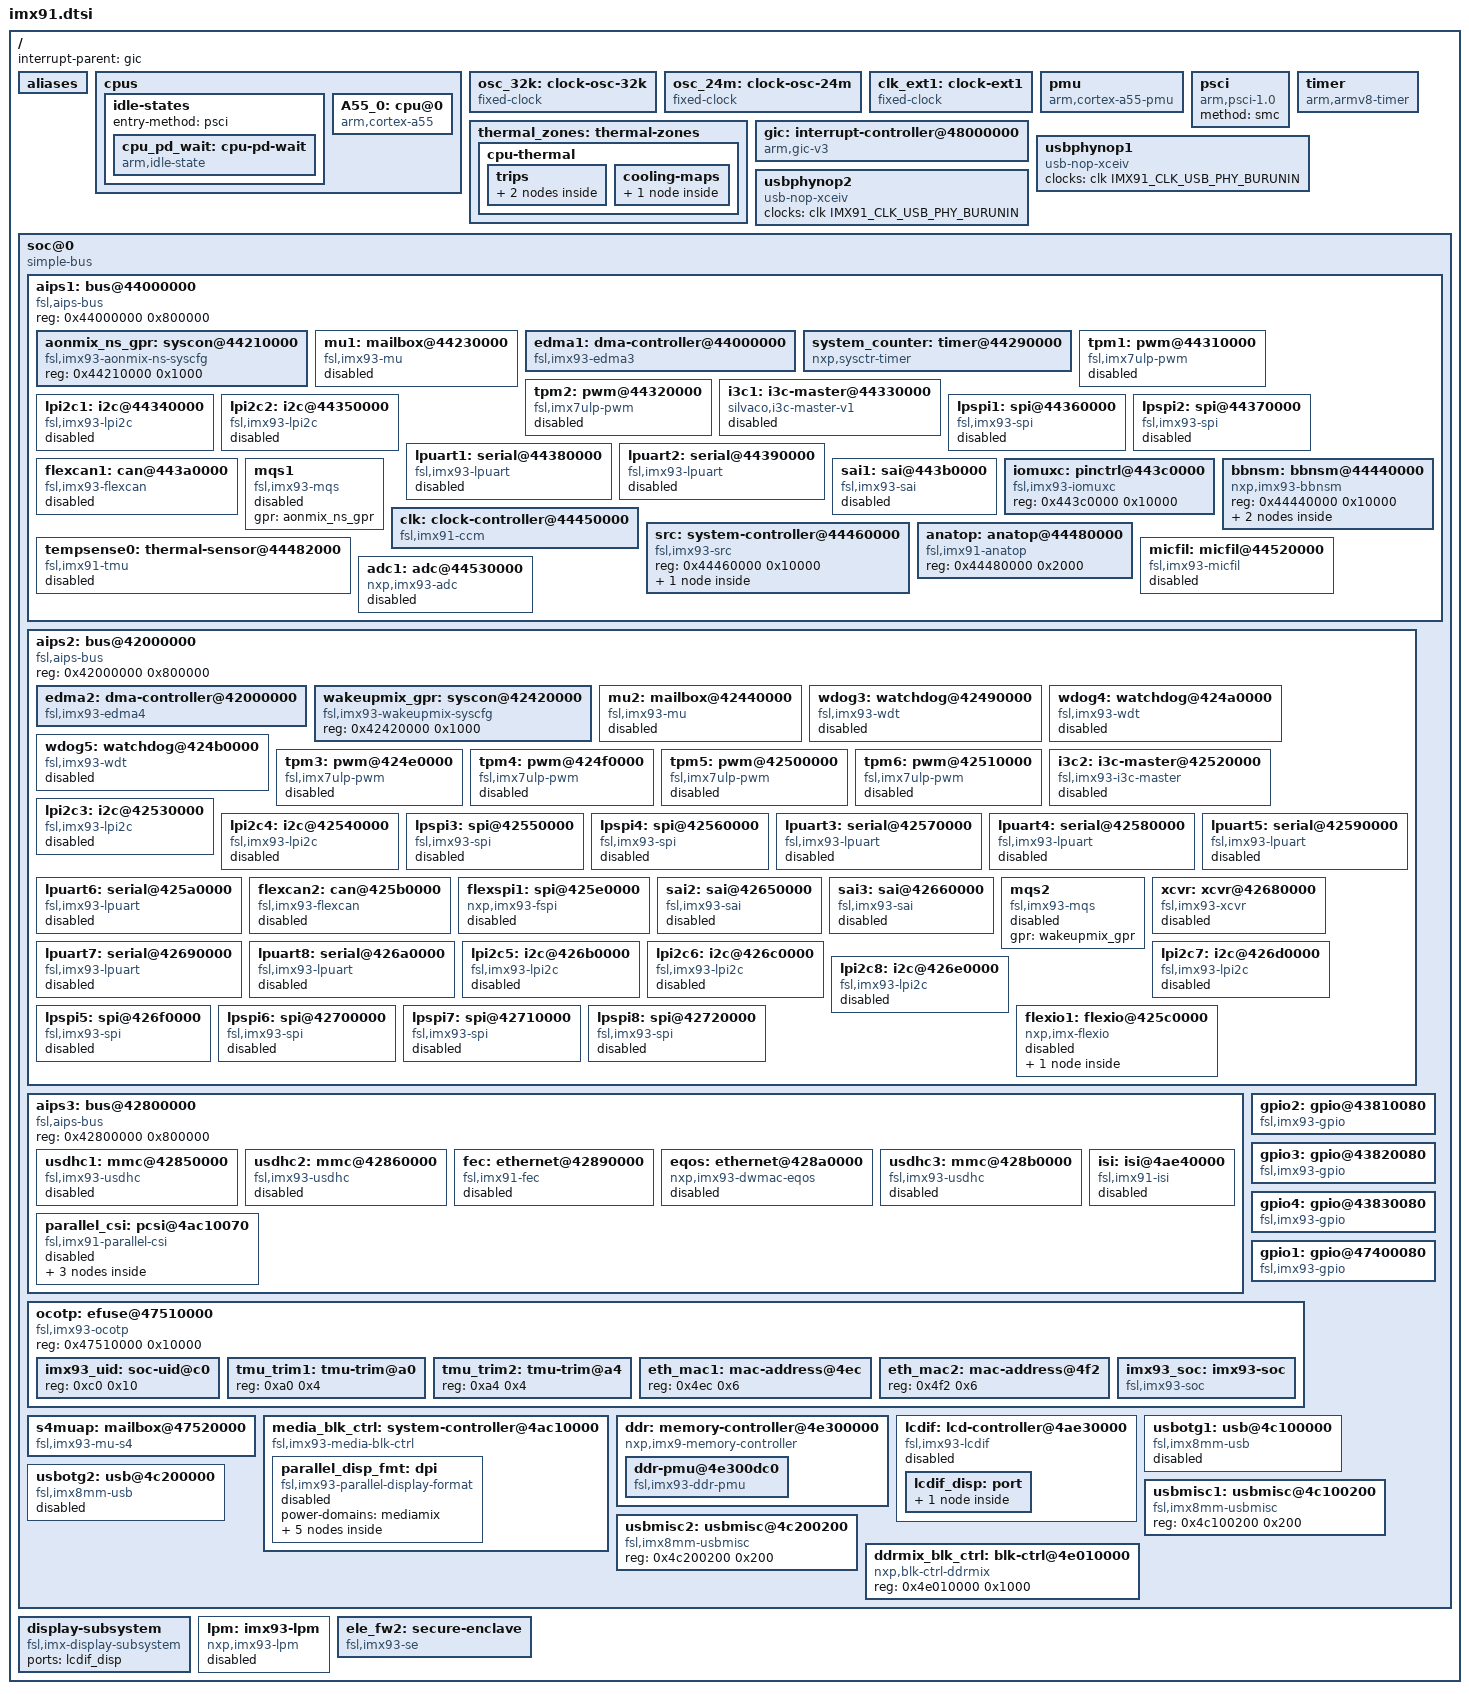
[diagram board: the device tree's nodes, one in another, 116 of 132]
// SPDX-License-Identifier: (GPL-2.0+ OR MIT)
/*
 * Copyright 2024 NXP
 */

#include <dt-bindings/clock/imx91-clock.h>
#include <dt-bindings/gpio/gpio.h>
#include <dt-bindings/input/input.h>
#include <dt-bindings/interrupt-controller/arm-gic.h>
#include <dt-bindings/power/fsl,imx91-power.h>
#include <dt-bindings/thermal/thermal.h>

#include "imx91-pinfunc.h"

/ {
	interrupt-parent = <&gic>;
	#address-cells = <2>;
	#size-cells = <2>;

	aliases {
		gpio0 = &gpio1;
		gpio1 = &gpio2;
		gpio2 = &gpio3;
		gpio3 = &gpio4;
		i2c0 = &lpi2c1;
		i2c1 = &lpi2c2;
		i2c2 = &lpi2c3;
		i2c3 = &lpi2c4;
		i2c4 = &lpi2c5;
		i2c5 = &lpi2c6;
		i2c6 = &lpi2c7;
		i2c7 = &lpi2c8;
		ethernet0 = &fec;
		ethernet1 = &eqos;
		mmc0 = &usdhc1;
		mmc1 = &usdhc2;
		mmc2 = &usdhc3;
		serial0 = &lpuart1;
		serial1 = &lpuart2;
		serial2 = &lpuart3;
		serial3 = &lpuart4;
		serial4 = &lpuart5;
		serial5 = &lpuart6;
		serial6 = &lpuart7;
		serial7 = &lpuart8;
		rtc0 = &bbnsm_rtc;
	};

	cpus {
		#address-cells = <1>;
		#size-cells = <0>;

		idle-states {
			entry-method = "psci";

			cpu_pd_wait: cpu-pd-wait {
				compatible = "arm,idle-state";
				arm,psci-suspend-param = <0x0010033>;
				local-timer-stop;
				entry-latency-us = <10000>;
				exit-latency-us = <7000>;
				min-residency-us = <27000>;
				wakeup-latency-us = <15000>;
			};
		};

		A55_0: cpu@0 {
			device_type = "cpu";
			compatible = "arm,cortex-a55";
			reg = <0x0>;
			enable-method = "psci";
			#cooling-cells = <2>;
			cpu-idle-states = <&cpu_pd_wait>;
		};
	};

	osc_32k: clock-osc-32k {
		compatible = "fixed-clock";
		#clock-cells = <0>;
		clock-frequency = <32768>;
		clock-output-names = "osc_32k";
	};

	osc_24m: clock-osc-24m {
		compatible = "fixed-clock";
		#clock-cells = <0>;
		clock-frequency = <24000000>;
		clock-output-names = "osc_24m";
	};

	clk_ext1: clock-ext1 {
		compatible = "fixed-clock";
		#clock-cells = <0>;
		clock-frequency = <133000000>;
		clock-output-names = "clk_ext1";
	};

	pmu {
		compatible = "arm,cortex-a55-pmu";
		interrupts = <GIC_PPI 7 (GIC_CPU_MASK_SIMPLE(2) | IRQ_TYPE_LEVEL_HIGH)>;
	};

	thermal_zones: thermal-zones {
		cpu-thermal {
			polling-delay-passive = <250>;
			polling-delay = <2000>;
			thermal-sensors = <&tempsense0>;
			trips {
				cpu_alert0: trip0 {
					temperature = <80000>;
					hysteresis = <2000>;
					type = "passive";
				};

				cpu_crit0: trip1 {
					temperature = <90000>;
					hysteresis = <2000>;
					type = "critical";
				};
			};

			cooling-maps {
				map0 {
					trip = <&cpu_alert0>;
					cooling-device =
						<&A55_0 THERMAL_NO_LIMIT THERMAL_NO_LIMIT>,
						<&lpm 0 1>;
				};
			};
		};
	};

	psci {
		compatible = "arm,psci-1.0";
		method = "smc";
	};

	timer {
		compatible = "arm,armv8-timer";
		interrupts = <GIC_PPI 13 (GIC_CPU_MASK_SIMPLE(6) | IRQ_TYPE_LEVEL_LOW)>,
			     <GIC_PPI 14 (GIC_CPU_MASK_SIMPLE(6) | IRQ_TYPE_LEVEL_LOW)>,
			     <GIC_PPI 11 (GIC_CPU_MASK_SIMPLE(6) | IRQ_TYPE_LEVEL_LOW)>,
			     <GIC_PPI 10 (GIC_CPU_MASK_SIMPLE(6) | IRQ_TYPE_LEVEL_LOW)>;
		clock-frequency = <24000000>;
		arm,no-tick-in-suspend;
		interrupt-parent = <&gic>;
	};

	gic: interrupt-controller@48000000 {
		compatible = "arm,gic-v3";
		reg = <0 0x48000000 0 0x10000>,
		      <0 0x48040000 0 0xc0000>;
		#interrupt-cells = <3>;
		interrupt-controller;
		interrupts = <GIC_PPI 9 IRQ_TYPE_LEVEL_HIGH>;
		interrupt-parent = <&gic>;
	};

	usbphynop1: usbphynop1 {
		compatible = "usb-nop-xceiv";
		clocks = <&clk IMX91_CLK_USB_PHY_BURUNIN>;
		clock-names = "main_clk";
	};

	usbphynop2: usbphynop2 {
		compatible = "usb-nop-xceiv";
		clocks = <&clk IMX91_CLK_USB_PHY_BURUNIN>;
		clock-names = "main_clk";
	};

	soc@0 {
		compatible = "simple-bus";
		#address-cells = <1>;
		#size-cells = <1>;
		ranges = <0x0 0x0 0x0 0x80000000>,
			 <0x28000000 0x0 0x28000000 0x10000000>;

		aips1: bus@44000000 {
			compatible = "fsl,aips-bus", "simple-bus";
			reg = <0x44000000 0x800000>;
			#address-cells = <1>;
			#size-cells = <1>;
			ranges;

			aonmix_ns_gpr: syscon@44210000 {
				compatible = "fsl,imx93-aonmix-ns-syscfg", "syscon";
				reg = <0x44210000 0x1000>;
			};

			mu1: mailbox@44230000 {
				compatible = "fsl,imx93-mu", "fsl,imx8ulp-mu";
				reg = <0x44230000 0x10000>;
				interrupts = <GIC_SPI 22 IRQ_TYPE_LEVEL_HIGH>;
				clocks = <&clk IMX91_CLK_MU1_B_GATE>;
				#mbox-cells = <2>;
				status = "disabled";
			};

			edma1: dma-controller@44000000{
				compatible = "fsl,imx93-edma3";
				reg = <0x44000000 0x200000>;
				#dma-cells = <3>;
				dma-channels = <31>;
				interrupts = <GIC_SPI 95 IRQ_TYPE_LEVEL_HIGH>,
					     <GIC_SPI 96 IRQ_TYPE_LEVEL_HIGH>,
					     <GIC_SPI 97 IRQ_TYPE_LEVEL_HIGH>,
					     <GIC_SPI 98 IRQ_TYPE_LEVEL_HIGH>,
					     <GIC_SPI 99 IRQ_TYPE_LEVEL_HIGH>,
					     <GIC_SPI 100 IRQ_TYPE_LEVEL_HIGH>,
					     <GIC_SPI 101 IRQ_TYPE_LEVEL_HIGH>,
					     <GIC_SPI 102 IRQ_TYPE_LEVEL_HIGH>,
					     <GIC_SPI 103 IRQ_TYPE_LEVEL_HIGH>,
					     <GIC_SPI 104 IRQ_TYPE_LEVEL_HIGH>,
					     <GIC_SPI 105 IRQ_TYPE_LEVEL_HIGH>,
					     <GIC_SPI 106 IRQ_TYPE_LEVEL_HIGH>,
					     <GIC_SPI 107 IRQ_TYPE_LEVEL_HIGH>,
					     <GIC_SPI 108 IRQ_TYPE_LEVEL_HIGH>,
					     <GIC_SPI 109 IRQ_TYPE_LEVEL_HIGH>,
					     <GIC_SPI 110 IRQ_TYPE_LEVEL_HIGH>,
					     <GIC_SPI 111 IRQ_TYPE_LEVEL_HIGH>,
					     <GIC_SPI 112 IRQ_TYPE_LEVEL_HIGH>,
					     <GIC_SPI 113 IRQ_TYPE_LEVEL_HIGH>,
					     <GIC_SPI 114 IRQ_TYPE_LEVEL_HIGH>,
					     <GIC_SPI 115 IRQ_TYPE_LEVEL_HIGH>,
					     <GIC_SPI 116 IRQ_TYPE_LEVEL_HIGH>,
					     <GIC_SPI 117 IRQ_TYPE_LEVEL_HIGH>,
					     <GIC_SPI 118 IRQ_TYPE_LEVEL_HIGH>,
					     <GIC_SPI 119 IRQ_TYPE_LEVEL_HIGH>,
					     <GIC_SPI 120 IRQ_TYPE_LEVEL_HIGH>,
					     <GIC_SPI 121 IRQ_TYPE_LEVEL_HIGH>,
					     <GIC_SPI 122 IRQ_TYPE_LEVEL_HIGH>,
					     <GIC_SPI 123 IRQ_TYPE_LEVEL_HIGH>,
					     <GIC_SPI 124 IRQ_TYPE_LEVEL_HIGH>,
					     <GIC_SPI 125 IRQ_TYPE_LEVEL_HIGH>,
					     <GIC_SPI 94 IRQ_TYPE_LEVEL_HIGH>;
				clocks = <&clk IMX91_CLK_EDMA1_GATE>;
				clock-names = "dma";
				status = "okay";
			};

			system_counter: timer@44290000 {
				compatible = "nxp,sysctr-timer";
				reg = <0x44290000 0x30000>;
				interrupts = <GIC_SPI 74 IRQ_TYPE_LEVEL_HIGH>;
				clocks = <&osc_24m>;
				clock-names = "per";
				nxp,no-divider;
			};

			tpm1: pwm@44310000 {
				compatible = "fsl,imx7ulp-pwm";
				reg = <0x44310000 0x1000>;
				clocks = <&clk IMX91_CLK_TPM1_GATE>;
				#pwm-cells = <3>;
				status = "disabled";
			};

			tpm2: pwm@44320000 {
				compatible = "fsl,imx7ulp-pwm";
				reg = <0x44320000 0x1000>;
				clocks = <&clk IMX91_CLK_TPM2_GATE>;
				assigned-clocks = <&clk IMX91_CLK_TPM2>;
				assigned-clock-parents = <&clk IMX91_CLK_24M>;
				assigned-clock-rates = <24000000>;
				#pwm-cells = <3>;
				status = "disabled";
			};

			i3c1: i3c-master@44330000 {
				#address-cells = <3>;
				#size-cells = <0>;
				compatible = "silvaco,i3c-master-v1";
				reg = <0x44330000 0x10000>;
				interrupts = <GIC_SPI 12 IRQ_TYPE_LEVEL_HIGH>;
				clocks = <&clk IMX91_CLK_BUS_AON>,
					 <&clk IMX91_CLK_I3C1_GATE>,
					 <&clk IMX91_CLK_DUMMY>;
				clock-names = "pclk", "fast_clk", "slow_clk";
				status = "disabled";
			};

			lpi2c1: i2c@44340000 {
				compatible = "fsl,imx93-lpi2c", "fsl,imx7ulp-lpi2c";
				reg = <0x44340000 0x10000>;
				#address-cells = <1>;
				#size-cells = <0>;
				interrupts = <GIC_SPI 13 IRQ_TYPE_LEVEL_HIGH>;
				clocks = <&clk IMX91_CLK_LPI2C1_GATE>,
					 <&clk IMX91_CLK_BUS_AON>;
				clock-names = "per", "ipg";
				dmas = <&edma1 7 0 0>, <&edma1 8 0 1>;
				dma-names = "tx","rx";
				status = "disabled";
			};

			lpi2c2: i2c@44350000 {
				compatible = "fsl,imx93-lpi2c", "fsl,imx7ulp-lpi2c";
				reg = <0x44350000 0x10000>;
				#address-cells = <1>;
				#size-cells = <0>;
				interrupts = <GIC_SPI 14 IRQ_TYPE_LEVEL_HIGH>;
				clocks = <&clk IMX91_CLK_LPI2C2_GATE>,
					 <&clk IMX91_CLK_BUS_AON>;
				clock-names = "per", "ipg";
				dmas = <&edma1 9 0 0>, <&edma1 10 0 1>;
				dma-names = "tx","rx";
				status = "disabled";
			};

			lpspi1: spi@44360000 {
				#address-cells = <1>;
				#size-cells = <0>;
				compatible = "fsl,imx93-spi", "fsl,imx7ulp-spi";
				reg = <0x44360000 0x10000>;
				interrupts = <GIC_SPI 16 IRQ_TYPE_LEVEL_HIGH>;
				clocks = <&clk IMX91_CLK_LPSPI1_GATE>,
					 <&clk IMX91_CLK_BUS_AON>;
				clock-names = "per", "ipg";
				dmas = <&edma1 11 0 0>, <&edma1 12 0 1>;
				dma-names = "tx","rx";
				status = "disabled";
			};

			lpspi2: spi@44370000 {
				#address-cells = <1>;
				#size-cells = <0>;
				compatible = "fsl,imx93-spi", "fsl,imx7ulp-spi";
				reg = <0x44370000 0x10000>;
				interrupts = <GIC_SPI 17 IRQ_TYPE_LEVEL_HIGH>;
				clocks = <&clk IMX91_CLK_LPSPI2_GATE>,
					 <&clk IMX91_CLK_BUS_AON>;
				clock-names = "per", "ipg";
				dmas = <&edma1 13 0 0>, <&edma1 14 0 1>;
				dma-names = "tx","rx";
				status = "disabled";
			};

			lpuart1: serial@44380000 {
				compatible = "fsl,imx93-lpuart", "fsl,imx8ulp-lpuart", "fsl,imx7ulp-lpuart";
				reg = <0x44380000 0x1000>;
				interrupts = <GIC_SPI 19 IRQ_TYPE_LEVEL_HIGH>;
				clocks = <&clk IMX91_CLK_LPUART1_GATE>;
				clock-names = "ipg";
				dmas = <&edma1 17 0 1>, <&edma1 16 0 0>;
				dma-names = "rx", "tx";
				status = "disabled";
			};

			lpuart2: serial@44390000 {
				compatible = "fsl,imx93-lpuart", "fsl,imx8ulp-lpuart", "fsl,imx7ulp-lpuart";
				reg = <0x44390000 0x1000>;
				interrupts = <GIC_SPI 20 IRQ_TYPE_LEVEL_HIGH>;
				clocks = <&clk IMX91_CLK_LPUART2_GATE>;
				clock-names = "ipg";
				dmas = <&edma1 19 0 1>, <&edma1 18 0 0>;
				dma-names = "rx", "tx";
				status = "disabled";
			};

			flexcan1: can@443a0000 {
				compatible = "fsl,imx93-flexcan";
				reg = <0x443a0000 0x10000>;
				interrupts = <GIC_SPI 8 IRQ_TYPE_LEVEL_HIGH>;
				clocks = <&clk IMX91_CLK_BUS_AON>,
					 <&clk IMX91_CLK_CAN1_GATE>;
				clock-names = "ipg", "per";
				assigned-clocks = <&clk IMX91_CLK_CAN1>;
				assigned-clock-parents = <&clk IMX91_CLK_SYS_PLL_PFD1_DIV2>;
				assigned-clock-rates = <40000000>;
				fsl,clk-source = /bits/ 8 <0>;
				fsl,stop-mode = <&aonmix_ns_gpr 0x14 0>;
				status = "disabled";
			};

			sai1: sai@443b0000 {
				compatible = "fsl,imx93-sai";
				reg = <0x443b0000 0x10000>;
				interrupts = <GIC_SPI 45 IRQ_TYPE_LEVEL_HIGH>;
				clocks = <&clk IMX91_CLK_SAI1_IPG>, <&clk IMX91_CLK_DUMMY>,
					 <&clk IMX91_CLK_SAI1_GATE>, <&clk IMX91_CLK_DUMMY>,
					 <&clk IMX91_CLK_DUMMY>;
				clock-names = "bus", "mclk0", "mclk1", "mclk2", "mclk3";
				dmas = <&edma1 22 0 1>, <&edma1 21 0 0>;
				dma-names = "rx", "tx";
				status = "disabled";
			};

			mqs1: mqs1 {
				compatible = "fsl,imx93-mqs";
				gpr = <&aonmix_ns_gpr>;
				status = "disabled";
			};

			iomuxc: pinctrl@443c0000 {
				compatible = "fsl,imx93-iomuxc";
				reg = <0x443c0000 0x10000>;
				status = "okay";
			};

			bbnsm: bbnsm@44440000 {
				compatible = "nxp,imx93-bbnsm", "syscon", "simple-mfd";
				reg = <0x44440000 0x10000>;

				bbnsm_rtc: rtc {
					compatible = "nxp,imx93-bbnsm-rtc";
					interrupts = <GIC_SPI 73 IRQ_TYPE_LEVEL_HIGH>;
				};

				bbnsm_pwrkey: pwrkey {
					compatible = "nxp,imx93-bbnsm-pwrkey";
					interrupts = <GIC_SPI 73 IRQ_TYPE_LEVEL_HIGH>;
					linux,code = <KEY_POWER>;
				};
			};

			clk: clock-controller@44450000 {
				compatible = "fsl,imx91-ccm";
				reg = <0x44450000 0x10000>;
				#clock-cells = <1>;
				clocks = <&osc_32k>, <&osc_24m>, <&clk_ext1>;
				clock-names = "osc_32k", "osc_24m", "clk_ext1";
				assigned-clocks = <&clk IMX91_CLK_AUDIO_PLL>, <&clk IMX91_CLK_VIDEO_PLL>,
						  <&clk IMX91_CLK_A55>;
				assigned-clock-parents = <0>, <0>, <&clk IMX91_CLK_SYS_PLL_PFD0>;
				assigned-clock-rates = <393216000>, <594000000>, <500000000>;
				status = "okay";
			};

			src: system-controller@44460000 {
				compatible = "fsl,imx93-src", "syscon";
				reg = <0x44460000 0x10000>;
				#address-cells = <1>;
				#size-cells = <1>;
				ranges;

				mediamix: power-domain@44462400 {
					compatible = "fsl,imx93-src-slice";
					reg = <0x44462400 0x400>, <0x44465800 0x400>;
					#power-domain-cells = <0>;
					clocks = <&clk IMX91_CLK_NIC_MEDIA_GATE>,
						 <&clk IMX91_CLK_MEDIA_APB>;
				};
			};

			anatop: anatop@44480000 {
				compatible = "fsl,imx91-anatop", "syscon";
				reg = <0x44480000 0x2000>;
			};

			tempsense0: thermal-sensor@44482000 {
				compatible = "fsl,imx91-tmu";
				reg = <0x44482000 0x1000>;
				#thermal-sensor-cells = <0>;
				clocks = <&clk IMX91_CLK_TMC_GATE>;
				nvmem-cells = <&tmu_trim1>, <&tmu_trim2>;
				nvmem-cell-names = "tmu-trim1", "tmu-trim2";
				status = "disabled";
			};

			micfil: micfil@44520000 {
				compatible = "fsl,imx93-micfil";
				reg = <0x44520000 0x10000>;
				interrupts = <GIC_SPI 202 IRQ_TYPE_LEVEL_HIGH>,
					     <GIC_SPI 201 IRQ_TYPE_LEVEL_HIGH>,
					     <GIC_SPI 200 IRQ_TYPE_LEVEL_HIGH>,
					     <GIC_SPI 199 IRQ_TYPE_LEVEL_HIGH>;
				clocks = <&clk IMX91_CLK_PDM_IPG>,
					 <&clk IMX91_CLK_PDM_GATE>,
					 <&clk IMX91_CLK_AUDIO_PLL>,
					 <&clk IMX91_CLK_DUMMY>;
				clock-names = "ipg_clk", "ipg_clk_app",
					     "pll8k", "clkext3";
				dmas = <&edma1 29 0 5>;
				dma-names = "rx";
				status = "disabled";
			};

			adc1: adc@44530000 {
				compatible = "nxp,imx93-adc";
				reg = <0x44530000 0x10000>;
				interrupts = <GIC_SPI 217 IRQ_TYPE_LEVEL_HIGH>,
						<GIC_SPI 218 IRQ_TYPE_LEVEL_HIGH>,
						<GIC_SPI 219 IRQ_TYPE_LEVEL_HIGH>,
						<GIC_SPI 268 IRQ_TYPE_LEVEL_HIGH>;
				clocks = <&clk IMX91_CLK_ADC1_GATE>;
				clock-names = "ipg";
				#io-channel-cells = <1>;
				status = "disabled";
			};
		};

		aips2: bus@42000000 {
			compatible = "fsl,aips-bus", "simple-bus";
			reg = <0x42000000 0x800000>;
			#address-cells = <1>;
			#size-cells = <1>;
			ranges;

			edma2: dma-controller@42000000{
				compatible = "fsl,imx93-edma4";
				reg = <0x42000000 0x210000>;
				#dma-cells = <3>;
				dma-channels = <64>;
				interrupts = <GIC_SPI 128 IRQ_TYPE_LEVEL_HIGH>,
					     <GIC_SPI 128 IRQ_TYPE_LEVEL_HIGH>,
					     <GIC_SPI 129 IRQ_TYPE_LEVEL_HIGH>,
					     <GIC_SPI 129 IRQ_TYPE_LEVEL_HIGH>,
					     <GIC_SPI 130 IRQ_TYPE_LEVEL_HIGH>,
					     <GIC_SPI 130 IRQ_TYPE_LEVEL_HIGH>,
					     <GIC_SPI 131 IRQ_TYPE_LEVEL_HIGH>,
					     <GIC_SPI 131 IRQ_TYPE_LEVEL_HIGH>,
					     <GIC_SPI 132 IRQ_TYPE_LEVEL_HIGH>,
					     <GIC_SPI 132 IRQ_TYPE_LEVEL_HIGH>,
					     <GIC_SPI 133 IRQ_TYPE_LEVEL_HIGH>,
					     <GIC_SPI 133 IRQ_TYPE_LEVEL_HIGH>,
					     <GIC_SPI 134 IRQ_TYPE_LEVEL_HIGH>,
					     <GIC_SPI 134 IRQ_TYPE_LEVEL_HIGH>,
					     <GIC_SPI 135 IRQ_TYPE_LEVEL_HIGH>,
					     <GIC_SPI 135 IRQ_TYPE_LEVEL_HIGH>,
					     <GIC_SPI 136 IRQ_TYPE_LEVEL_HIGH>,
					     <GIC_SPI 136 IRQ_TYPE_LEVEL_HIGH>,
					     <GIC_SPI 137 IRQ_TYPE_LEVEL_HIGH>,
					     <GIC_SPI 137 IRQ_TYPE_LEVEL_HIGH>,
					     <GIC_SPI 138 IRQ_TYPE_LEVEL_HIGH>,
					     <GIC_SPI 138 IRQ_TYPE_LEVEL_HIGH>,
					     <GIC_SPI 139 IRQ_TYPE_LEVEL_HIGH>,
					     <GIC_SPI 139 IRQ_TYPE_LEVEL_HIGH>,
					     <GIC_SPI 140 IRQ_TYPE_LEVEL_HIGH>,
					     <GIC_SPI 140 IRQ_TYPE_LEVEL_HIGH>,
					     <GIC_SPI 141 IRQ_TYPE_LEVEL_HIGH>,
					     <GIC_SPI 141 IRQ_TYPE_LEVEL_HIGH>,
					     <GIC_SPI 142 IRQ_TYPE_LEVEL_HIGH>,
					     <GIC_SPI 142 IRQ_TYPE_LEVEL_HIGH>,
					     <GIC_SPI 143 IRQ_TYPE_LEVEL_HIGH>,
					     <GIC_SPI 143 IRQ_TYPE_LEVEL_HIGH>,
					     <GIC_SPI 144 IRQ_TYPE_LEVEL_HIGH>,
					     <GIC_SPI 144 IRQ_TYPE_LEVEL_HIGH>,
					     <GIC_SPI 145 IRQ_TYPE_LEVEL_HIGH>,
					     <GIC_SPI 145 IRQ_TYPE_LEVEL_HIGH>,
					     <GIC_SPI 146 IRQ_TYPE_LEVEL_HIGH>,
					     <GIC_SPI 146 IRQ_TYPE_LEVEL_HIGH>,
					     <GIC_SPI 147 IRQ_TYPE_LEVEL_HIGH>,
					     <GIC_SPI 147 IRQ_TYPE_LEVEL_HIGH>,
					     <GIC_SPI 148 IRQ_TYPE_LEVEL_HIGH>,
					     <GIC_SPI 148 IRQ_TYPE_LEVEL_HIGH>,
					     <GIC_SPI 149 IRQ_TYPE_LEVEL_HIGH>,
					     <GIC_SPI 149 IRQ_TYPE_LEVEL_HIGH>,
					     <GIC_SPI 150 IRQ_TYPE_LEVEL_HIGH>,
					     <GIC_SPI 150 IRQ_TYPE_LEVEL_HIGH>,
					     <GIC_SPI 151 IRQ_TYPE_LEVEL_HIGH>,
					     <GIC_SPI 151 IRQ_TYPE_LEVEL_HIGH>,
					     <GIC_SPI 152 IRQ_TYPE_LEVEL_HIGH>,
					     <GIC_SPI 152 IRQ_TYPE_LEVEL_HIGH>,
					     <GIC_SPI 153 IRQ_TYPE_LEVEL_HIGH>,
					     <GIC_SPI 153 IRQ_TYPE_LEVEL_HIGH>,
					     <GIC_SPI 154 IRQ_TYPE_LEVEL_HIGH>,
					     <GIC_SPI 154 IRQ_TYPE_LEVEL_HIGH>,
					     <GIC_SPI 155 IRQ_TYPE_LEVEL_HIGH>,
					     <GIC_SPI 155 IRQ_TYPE_LEVEL_HIGH>,
					     <GIC_SPI 156 IRQ_TYPE_LEVEL_HIGH>,
					     <GIC_SPI 156 IRQ_TYPE_LEVEL_HIGH>,
					     <GIC_SPI 157 IRQ_TYPE_LEVEL_HIGH>,
					     <GIC_SPI 157 IRQ_TYPE_LEVEL_HIGH>,
					     <GIC_SPI 158 IRQ_TYPE_LEVEL_HIGH>,
					     <GIC_SPI 158 IRQ_TYPE_LEVEL_HIGH>,
					     <GIC_SPI 159 IRQ_TYPE_LEVEL_HIGH>,
					     <GIC_SPI 159 IRQ_TYPE_LEVEL_HIGH>,
					     <GIC_SPI 127 IRQ_TYPE_LEVEL_HIGH>;
				clocks = <&clk IMX91_CLK_EDMA2_GATE>;
				clock-names = "dma";
				status = "okay";
			};

			wakeupmix_gpr: syscon@42420000 {
				compatible = "fsl,imx93-wakeupmix-syscfg", "syscon";
				reg = <0x42420000 0x1000>;
			};

			mu2: mailbox@42440000 {
				compatible = "fsl,imx93-mu", "fsl,imx8ulp-mu";
				reg = <0x42440000 0x10000>;
				interrupts = <GIC_SPI 24 IRQ_TYPE_LEVEL_HIGH>;
				clocks = <&clk IMX91_CLK_MU2_B_GATE>;
				#mbox-cells = <2>;
				status = "disabled";
			};

			wdog3: watchdog@42490000 {
				compatible = "fsl,imx93-wdt";
				reg = <0x42490000 0x10000>;
				interrupts = <GIC_SPI 79 IRQ_TYPE_LEVEL_HIGH>;
				clocks = <&clk IMX91_CLK_WDOG3_GATE>;
				timeout-sec = <40>;
				fsl,ext-reset-output;
				status = "disabled";
			};

			wdog4: watchdog@424a0000 {
				compatible = "fsl,imx93-wdt";
				reg = <0x424a0000 0x10000>;
				interrupts = <GIC_SPI 80 IRQ_TYPE_LEVEL_HIGH>;
				clocks = <&clk IMX91_CLK_WDOG4_GATE>;
				timeout-sec = <40>;
				status = "disabled";
			};

			wdog5: watchdog@424b0000 {
				compatible = "fsl,imx93-wdt";
				reg = <0x424b0000 0x10000>;
				interrupts = <GIC_SPI 81 IRQ_TYPE_LEVEL_HIGH>;
				clocks = <&clk IMX91_CLK_WDOG5_GATE>;
				timeout-sec = <40>;
				status = "disabled";
			};

			tpm3: pwm@424e0000 {
				compatible = "fsl,imx7ulp-pwm";
				reg = <0x424e0000 0x1000>;
				clocks = <&clk IMX91_CLK_TPM3_GATE>;
				#pwm-cells = <3>;
				status = "disabled";
			};

			tpm4: pwm@424f0000 {
				compatible = "fsl,imx7ulp-pwm";
				reg = <0x424f0000 0x1000>;
				clocks = <&clk IMX91_CLK_TPM4_GATE>;
				assigned-clocks = <&clk IMX91_CLK_TPM4>;
				assigned-clock-parents = <&clk IMX91_CLK_24M>;
				assigned-clock-rates = <24000000>;
				#pwm-cells = <3>;
				status = "disabled";
			};

			tpm5: pwm@42500000 {
				compatible = "fsl,imx7ulp-pwm";
				reg = <0x42500000 0x1000>;
				clocks = <&clk IMX91_CLK_TPM5_GATE>;
				assigned-clocks = <&clk IMX91_CLK_TPM5>;
				assigned-clock-parents = <&clk IMX91_CLK_24M>;
				assigned-clock-rates = <24000000>;
				#pwm-cells = <3>;
				status = "disabled";
			};

			tpm6: pwm@42510000 {
				compatible = "fsl,imx7ulp-pwm";
				reg = <0x42510000 0x1000>;
				clocks = <&clk IMX91_CLK_TPM6_GATE>;
				assigned-clocks = <&clk IMX91_CLK_TPM6>;
				assigned-clock-parents = <&clk IMX91_CLK_24M>;
				assigned-clock-rates = <24000000>;
				#pwm-cells = <3>;
				status = "disabled";
			};

			i3c2: i3c-master@42520000 {
				#address-cells = <3>;
				#size-cells = <0>;
				compatible = "fsl,imx93-i3c-master", "silvaco,i3c-master";
				reg = <0x42520000 0x10000>;
				interrupts = <GIC_SPI 61 IRQ_TYPE_LEVEL_HIGH>;
				clocks = <&clk IMX91_CLK_BUS_WAKEUP>,
					 <&clk IMX91_CLK_I3C2_GATE>,
					 <&clk IMX91_CLK_DUMMY>;
				clock-names = "pclk", "fast_clk", "slow_clk";
				status = "disabled";
			};

			lpi2c3: i2c@42530000 {
				compatible = "fsl,imx93-lpi2c", "fsl,imx7ulp-lpi2c";
				reg = <0x42530000 0x10000>;
				#address-cells = <1>;
				#size-cells = <0>;
				interrupts = <GIC_SPI 62 IRQ_TYPE_LEVEL_HIGH>;
				clocks = <&clk IMX91_CLK_LPI2C3_GATE>,
					 <&clk IMX91_CLK_BUS_WAKEUP>;
				clock-names = "per", "ipg";
				dmas = <&edma2 8 0 0>, <&edma2 9 0 1>;
				dma-names = "tx","rx";
				status = "disabled";
			};

			lpi2c4: i2c@42540000 {
				compatible = "fsl,imx93-lpi2c", "fsl,imx7ulp-lpi2c";
				reg = <0x42540000 0x10000>;
				#address-cells = <1>;
				#size-cells = <0>;
				interrupts = <GIC_SPI 63 IRQ_TYPE_LEVEL_HIGH>;
				clocks = <&clk IMX91_CLK_LPI2C4_GATE>,
					 <&clk IMX91_CLK_BUS_WAKEUP>;
				clock-names = "per", "ipg";
				dmas = <&edma2 10 0 0>, <&edma2 11 0 1>;
				dma-names = "tx","rx";
				status = "disabled";
			};

			lpspi3: spi@42550000 {
				#address-cells = <1>;
				#size-cells = <0>;
				compatible = "fsl,imx93-spi", "fsl,imx7ulp-spi";
				reg = <0x42550000 0x10000>;
				interrupts = <GIC_SPI 65 IRQ_TYPE_LEVEL_HIGH>;
				clocks = <&clk IMX91_CLK_LPSPI3_GATE>,
					 <&clk IMX91_CLK_BUS_WAKEUP>;
				clock-names = "per", "ipg";
				dmas = <&edma2 12 0 0>, <&edma2 13 0 1>;
				dma-names = "tx","rx";
				status = "disabled";
			};

			lpspi4: spi@42560000 {
				#address-cells = <1>;
				#size-cells = <0>;
				compatible = "fsl,imx93-spi", "fsl,imx7ulp-spi";
				reg = <0x42560000 0x10000>;
				interrupts = <GIC_SPI 66 IRQ_TYPE_LEVEL_HIGH>;
				clocks = <&clk IMX91_CLK_LPSPI4_GATE>,
					 <&clk IMX91_CLK_BUS_WAKEUP>;
				clock-names = "per", "ipg";
				dmas = <&edma2 14 0 0>, <&edma2 15 0 1>;
				dma-names = "tx","rx";
				status = "disabled";
			};

			lpuart3: serial@42570000 {
				compatible = "fsl,imx93-lpuart", "fsl,imx8ulp-lpuart", "fsl,imx7ulp-lpuart";
				reg = <0x42570000 0x1000>;
				interrupts = <GIC_SPI 68 IRQ_TYPE_LEVEL_HIGH>;
				clocks = <&clk IMX91_CLK_LPUART3_GATE>;
				clock-names = "ipg";
				dmas = <&edma2 18 0 1>, <&edma2 17 0 0>;
				dma-names = "rx", "tx";
				status = "disabled";
			};

			lpuart4: serial@42580000 {
				compatible = "fsl,imx93-lpuart", "fsl,imx8ulp-lpuart", "fsl,imx7ulp-lpuart";
				reg = <0x42580000 0x1000>;
				interrupts = <GIC_SPI 69 IRQ_TYPE_LEVEL_HIGH>;
				clocks = <&clk IMX91_CLK_LPUART4_GATE>;
				clock-names = "ipg";
				dmas = <&edma2 20 0 1>, <&edma2 19 0 0>;
				dma-names = "rx", "tx";
				status = "disabled";
			};

			lpuart5: serial@42590000 {
				compatible = "fsl,imx93-lpuart", "fsl,imx8ulp-lpuart", "fsl,imx7ulp-lpuart";
				reg = <0x42590000 0x1000>;
				interrupts = <GIC_SPI 70 IRQ_TYPE_LEVEL_HIGH>;
				clocks = <&clk IMX91_CLK_LPUART5_GATE>;
				clock-names = "ipg";
				dmas = <&edma2 22 0 1>, <&edma2 21 0 0>;
				dma-names = "rx", "tx";
				status = "disabled";
			};

			lpuart6: serial@425a0000 {
				compatible = "fsl,imx93-lpuart", "fsl,imx8ulp-lpuart", "fsl,imx7ulp-lpuart";
				reg = <0x425a0000 0x1000>;
				interrupts = <GIC_SPI 71 IRQ_TYPE_LEVEL_HIGH>;
				clocks = <&clk IMX91_CLK_LPUART6_GATE>;
				clock-names = "ipg";
				dmas = <&edma2 24 0 1>, <&edma2 23 0 0>;
				dma-names = "rx", "tx";
				status = "disabled";
			};

			flexcan2: can@425b0000 {
				compatible = "fsl,imx93-flexcan";
				reg = <0x425b0000 0x10000>;
				interrupts = <GIC_SPI 51 IRQ_TYPE_LEVEL_HIGH>;
				clocks = <&clk IMX91_CLK_BUS_WAKEUP>,
					 <&clk IMX91_CLK_CAN2_GATE>;
				clock-names = "ipg", "per";
				assigned-clocks = <&clk IMX91_CLK_CAN2>;
				assigned-clock-parents = <&clk IMX91_CLK_SYS_PLL_PFD1_DIV2>;
				assigned-clock-rates = <40000000>;
				fsl,clk-source = /bits/ 8 <0>;
				fsl,stop-mode = <&wakeupmix_gpr 0x0C 2>;
				status = "disabled";
			};

			flexspi1: spi@425e0000 {
				compatible = "nxp,imx93-fspi", "nxp,imx8mm-fspi";
				reg = <0x425e0000 0x10000>, <0x28000000 0x10000000>;
				reg-names = "fspi_base", "fspi_mmap";
				#address-cells = <1>;
				#size-cells = <0>;
				interrupts = <GIC_SPI 55 IRQ_TYPE_LEVEL_HIGH>;
				clocks = <&clk IMX91_CLK_FLEXSPI1_GATE>,
					 <&clk IMX91_CLK_FLEXSPI1_GATE>;
				clock-names = "fspi_en", "fspi";
				assigned-clocks = <&clk IMX91_CLK_FLEXSPI1>;
				assigned-clock-parents = <&clk IMX91_CLK_SYS_PLL_PFD1>;
				status = "disabled";
			};

			sai2: sai@42650000 {
				compatible = "fsl,imx93-sai";
				reg = <0x42650000 0x10000>;
				interrupts = <GIC_SPI 170 IRQ_TYPE_LEVEL_HIGH>;
				clocks = <&clk IMX91_CLK_SAI2_IPG>, <&clk IMX91_CLK_DUMMY>,
					 <&clk IMX91_CLK_SAI2_GATE>,
					 <&clk IMX91_CLK_DUMMY>, <&clk IMX91_CLK_DUMMY>;
				clock-names = "bus", "mclk0", "mclk1", "mclk2", "mclk3";
				dmas = <&edma2 59 0 1>, <&edma2 58 0 0>;
				dma-names = "rx", "tx";
				status = "disabled";
			};

			sai3: sai@42660000 {
				compatible = "fsl,imx93-sai";
				reg = <0x42660000 0x10000>;
				interrupts = <GIC_SPI 171 IRQ_TYPE_LEVEL_HIGH>;
				clocks = <&clk IMX91_CLK_SAI3_IPG>, <&clk IMX91_CLK_DUMMY>,
					 <&clk IMX91_CLK_SAI3_GATE>,
					 <&clk IMX91_CLK_DUMMY>, <&clk IMX91_CLK_DUMMY>;
				clock-names = "bus", "mclk0", "mclk1", "mclk2", "mclk3";
				dmas = <&edma2 61 0 1>, <&edma2 60 0 0>;
				dma-names = "rx", "tx";
				status = "disabled";
			};

			mqs2: mqs2 {
				compatible = "fsl,imx93-mqs";
				gpr = <&wakeupmix_gpr>;
				status = "disabled";
			};

			xcvr: xcvr@42680000 {
				compatible = "fsl,imx93-xcvr";
				reg = <0x42680000 0x800>,
					  <0x42680800 0x400>,
					  <0x42680c00 0x080>,
					  <0x42680e00 0x080>;
				reg-names = "ram", "regs", "rxfifo",
						    "txfifo";
				interrupts = /* XCVR IRQ 0 */
					     <GIC_SPI 203 IRQ_TYPE_LEVEL_HIGH>,
						 /* XCVR IRQ 1 */
					     <GIC_SPI 204 IRQ_TYPE_LEVEL_HIGH>;
				clocks = <&clk IMX91_CLK_SPDIF_IPG>,
					 <&clk IMX91_CLK_SPDIF_GATE>,
					 <&clk IMX91_CLK_DUMMY>,
					 <&clk IMX91_CLK_AUD_XCVR_GATE>;
				clock-names = "ipg", "phy", "spba", "pll_ipg";
				dmas = <&edma2 65 0 1>, <&edma2 66 0 0>;
				dma-names = "rx", "tx";
				status = "disabled";
			};

			lpuart7: serial@42690000 {
				compatible = "fsl,imx93-lpuart", "fsl,imx8ulp-lpuart", "fsl,imx7ulp-lpuart";
				reg = <0x42690000 0x1000>;
				interrupts = <GIC_SPI 210 IRQ_TYPE_LEVEL_HIGH>;
				clocks = <&clk IMX91_CLK_LPUART7_GATE>;
				clock-names = "ipg";
				dmas = <&edma2 88 0 1>, <&edma2 87 0 0>;
				dma-names = "rx", "tx";
				status = "disabled";
			};

			lpuart8: serial@426a0000 {
				compatible = "fsl,imx93-lpuart", "fsl,imx8ulp-lpuart", "fsl,imx7ulp-lpuart";
				reg = <0x426a0000 0x1000>;
				interrupts = <GIC_SPI 211 IRQ_TYPE_LEVEL_HIGH>;
				clocks = <&clk IMX91_CLK_LPUART8_GATE>;
				clock-names = "ipg";
				dmas = <&edma2 90 0 1>, <&edma2 89 0 0>;
				dma-names = "rx", "tx";
				status = "disabled";
			};

			lpi2c5: i2c@426b0000 {
				compatible = "fsl,imx93-lpi2c", "fsl,imx7ulp-lpi2c";
				reg = <0x426b0000 0x10000>;
				#address-cells = <1>;
				#size-cells = <0>;
				interrupts = <GIC_SPI 195 IRQ_TYPE_LEVEL_HIGH>;
				clocks = <&clk IMX91_CLK_LPI2C5_GATE>,
					 <&clk IMX91_CLK_BUS_WAKEUP>;
				clock-names = "per", "ipg";
				dmas = <&edma2 71 0 0>, <&edma2 72 0 1>;
				dma-names = "tx","rx";
				status = "disabled";
			};

			lpi2c6: i2c@426c0000 {
				compatible = "fsl,imx93-lpi2c", "fsl,imx7ulp-lpi2c";
				reg = <0x426c0000 0x10000>;
				#address-cells = <1>;
				#size-cells = <0>;
				interrupts = <GIC_SPI 196 IRQ_TYPE_LEVEL_HIGH>;
				clocks = <&clk IMX91_CLK_LPI2C6_GATE>,
					 <&clk IMX91_CLK_BUS_WAKEUP>;
				clock-names = "per", "ipg";
				dmas = <&edma2 73 0 0>, <&edma2 74 0 1>;
				dma-names = "tx","rx";
				status = "disabled";
			};

			lpi2c7: i2c@426d0000 {
				compatible = "fsl,imx93-lpi2c", "fsl,imx7ulp-lpi2c";
				reg = <0x426d0000 0x10000>;
				#address-cells = <1>;
				#size-cells = <0>;
				interrupts = <GIC_SPI 197 IRQ_TYPE_LEVEL_HIGH>;
				clocks = <&clk IMX91_CLK_LPI2C7_GATE>,
					 <&clk IMX91_CLK_BUS_WAKEUP>;
				clock-names = "per", "ipg";
				dmas = <&edma2 75 0 0>, <&edma2 76 0 1>;
				dma-names = "tx","rx";
				status = "disabled";
			};

			lpi2c8: i2c@426e0000 {
				compatible = "fsl,imx93-lpi2c", "fsl,imx7ulp-lpi2c";
				reg = <0x426e0000 0x10000>;
				#address-cells = <1>;
				#size-cells = <0>;
				interrupts = <GIC_SPI 198 IRQ_TYPE_LEVEL_HIGH>;
				clocks = <&clk IMX91_CLK_LPI2C8_GATE>,
					 <&clk IMX91_CLK_BUS_WAKEUP>;
				clock-names = "per", "ipg";
				dmas = <&edma2 77 0 0>, <&edma2 78 0 1>;
				dma-names = "tx","rx";
				status = "disabled";
			};

			lpspi5: spi@426f0000 {
				#address-cells = <1>;
				#size-cells = <0>;
				compatible = "fsl,imx93-spi", "fsl,imx7ulp-spi";
				reg = <0x426f0000 0x10000>;
				interrupts = <GIC_SPI 191 IRQ_TYPE_LEVEL_HIGH>;
				clocks = <&clk IMX91_CLK_LPSPI5_GATE>,
					 <&clk IMX91_CLK_BUS_WAKEUP>;
				clock-names = "per", "ipg";
				dmas = <&edma2 79 0 0>, <&edma2 80 0 1>;
				dma-names = "tx","rx";
				status = "disabled";
			};

			lpspi6: spi@42700000 {
				#address-cells = <1>;
				#size-cells = <0>;
				compatible = "fsl,imx93-spi", "fsl,imx7ulp-spi";
				reg = <0x42700000 0x10000>;
				interrupts = <GIC_SPI 192 IRQ_TYPE_LEVEL_HIGH>;
				clocks = <&clk IMX91_CLK_LPSPI6_GATE>,
					 <&clk IMX91_CLK_BUS_WAKEUP>;
				clock-names = "per", "ipg";
				dmas = <&edma2 81 0 0>, <&edma2 82 0 1>;
				dma-names = "tx","rx";
				status = "disabled";
			};

			lpspi7: spi@42710000 {
				#address-cells = <1>;
				#size-cells = <0>;
				compatible = "fsl,imx93-spi", "fsl,imx7ulp-spi";
				reg = <0x42710000 0x10000>;
				interrupts = <GIC_SPI 193 IRQ_TYPE_LEVEL_HIGH>;
				clocks = <&clk IMX91_CLK_LPSPI7_GATE>,
					 <&clk IMX91_CLK_BUS_WAKEUP>;
				clock-names = "per", "ipg";
				dmas = <&edma2 83 0 0>, <&edma2 84 0 1>;
				dma-names = "tx","rx";
				status = "disabled";
			};

			lpspi8: spi@42720000 {
				#address-cells = <1>;
				#size-cells = <0>;
				compatible = "fsl,imx93-spi", "fsl,imx7ulp-spi";
				reg = <0x42720000 0x10000>;
				interrupts = <GIC_SPI 194 IRQ_TYPE_LEVEL_HIGH>;
				clocks = <&clk IMX91_CLK_LPSPI8_GATE>,
					 <&clk IMX91_CLK_BUS_WAKEUP>;
				clock-names = "per", "ipg";
				dmas = <&edma2 85 0 0>, <&edma2 86 0 1>;
				dma-names = "tx","rx";
				status = "disabled";
			};

			flexio1: flexio@425c0000 {
				compatible = "nxp,imx-flexio";
				reg = <0x425c0000 0x10000>;
				interrupts = <GIC_SPI 53 IRQ_TYPE_LEVEL_HIGH>;
				clocks = <&clk IMX91_CLK_FLEXIO1_GATE>,
					 <&clk IMX91_CLK_FLEXIO1_GATE>;
				clock-names = "per", "ipg";
				assigned-clocks = <&clk IMX91_CLK_FLEXIO1_GATE>;
				assigned-clock-parents = <&clk IMX91_CLK_FLEXIO1>;
				assigned-clock-rates = <24000000>;
				status = "disabled";

				flexio_i2c: i2c-master {
					#address-cells = <1>;
					#size-cells = <0>;
					compatible = "nxp,imx-flexio-i2c-master";
					clock-frequency = <100000>;
					status = "disabled";
				};
			};
		};

		aips3: bus@42800000 {
			compatible = "fsl,aips-bus", "simple-bus";
			reg = <0x42800000 0x800000>;
			#address-cells = <1>;
			#size-cells = <1>;
			ranges;

			usdhc1: mmc@42850000 {
				compatible = "fsl,imx93-usdhc", "fsl,imx8mm-usdhc";
				reg = <0x42850000 0x10000>;
				interrupts = <GIC_SPI 86 IRQ_TYPE_LEVEL_HIGH>;
				clocks = <&clk IMX91_CLK_BUS_WAKEUP>,
					 <&clk IMX91_CLK_WAKEUP_AXI>,
					 <&clk IMX91_CLK_USDHC1_GATE>;
				clock-names = "ipg", "ahb", "per";
				assigned-clocks = <&clk IMX91_CLK_USDHC1>;
				assigned-clock-parents = <&clk IMX91_CLK_SYS_PLL_PFD1>;
				assigned-clock-rates = <400000000>;
				bus-width = <8>;
				fsl,tuning-start-tap = <1>;
				fsl,tuning-step= <2>;
				status = "disabled";
			};

			usdhc2: mmc@42860000 {
				compatible = "fsl,imx93-usdhc", "fsl,imx8mm-usdhc";
				reg = <0x42860000 0x10000>;
				interrupts = <GIC_SPI 87 IRQ_TYPE_LEVEL_HIGH>;
				clocks = <&clk IMX91_CLK_BUS_WAKEUP>,
					 <&clk IMX91_CLK_WAKEUP_AXI>,
					 <&clk IMX91_CLK_USDHC2_GATE>;
				clock-names = "ipg", "ahb", "per";
				assigned-clocks = <&clk IMX91_CLK_USDHC2>;
				assigned-clock-parents = <&clk IMX91_CLK_SYS_PLL_PFD1>;
				assigned-clock-rates = <400000000>;
				bus-width = <4>;
				fsl,tuning-start-tap = <1>;
				fsl,tuning-step= <2>;
				status = "disabled";
			};

			fec: ethernet@42890000 {
				compatible = "fsl,imx91-fec", "fsl,imx8mp-fec", "fsl,imx8mq-fec";
				reg = <0x42890000 0x10000>;
				interrupts = <GIC_SPI 179 IRQ_TYPE_LEVEL_HIGH>,
					     <GIC_SPI 180 IRQ_TYPE_LEVEL_HIGH>,
					     <GIC_SPI 181 IRQ_TYPE_LEVEL_HIGH>,
					     <GIC_SPI 182 IRQ_TYPE_LEVEL_HIGH>;
				clocks = <&clk IMX91_CLK_ENET2_REGULAR_GATE>,
					 <&clk IMX91_CLK_ENET2_REGULAR_GATE>,
					 <&clk IMX91_CLK_ENET_TIMER>,
					 <&clk IMX91_CLK_ENET2_REGULAR>,
					 <&clk IMX91_CLK_DUMMY>;
				clock-names = "ipg", "ahb", "ptp",
					      "enet_clk_ref", "enet_out";
				assigned-clocks = <&clk IMX91_CLK_ENET_TIMER>,
						  <&clk IMX91_CLK_ENET2_REGULAR>;
				assigned-clock-parents = <&clk IMX91_CLK_SYS_PLL_PFD1_DIV2>,
							 <&clk IMX91_CLK_SYS_PLL_PFD0_DIV2>;
				assigned-clock-rates = <100000000>, <250000000>;
				fsl,num-tx-queues = <3>;
				fsl,num-rx-queues = <3>;
				fsl,stop-mode = <&wakeupmix_gpr 0x0c 1>;
				status = "disabled";
			};

			eqos: ethernet@428a0000 {
				compatible = "nxp,imx93-dwmac-eqos", "snps,dwmac-5.10a";
				reg = <0x428a0000 0x10000>;
				interrupts = <GIC_SPI 183 IRQ_TYPE_LEVEL_HIGH>,
					     <GIC_SPI 184 IRQ_TYPE_LEVEL_HIGH>;
				interrupt-names = "eth_wake_irq", "macirq";
				clocks = <&clk IMX91_CLK_ENET1_QOS_TSN_GATE>,
					 <&clk IMX91_CLK_ENET1_QOS_TSN_GATE>,
					 <&clk IMX91_CLK_ENET_TIMER>,
					 <&clk IMX91_CLK_ENET1_QOS_TSN>,
					 <&clk IMX91_CLK_ENET1_QOS_TSN_GATE>;
				clock-names = "stmmaceth", "pclk", "ptp_ref", "tx", "mem";
				assigned-clocks = <&clk IMX91_CLK_ENET_TIMER>,
						  <&clk IMX91_CLK_ENET1_QOS_TSN>;
				assigned-clock-parents = <&clk IMX91_CLK_SYS_PLL_PFD1_DIV2>,
							 <&clk IMX91_CLK_SYS_PLL_PFD0_DIV2>;
				assigned-clock-rates = <100000000>, <250000000>;
				intf_mode = <&wakeupmix_gpr 0x28>;
				snps,clk-csr = <0>;
				nvmem-cells = <&eth_mac2>;
				nvmem-cell-names = "mac-address";
				status = "disabled";
			};

			usdhc3: mmc@428b0000 {
				compatible = "fsl,imx93-usdhc", "fsl,imx8mm-usdhc";
				reg = <0x428b0000 0x10000>;
				interrupts = <GIC_SPI 205 IRQ_TYPE_LEVEL_HIGH>;
				clocks = <&clk IMX91_CLK_BUS_WAKEUP>,
					 <&clk IMX91_CLK_WAKEUP_AXI>,
					 <&clk IMX91_CLK_USDHC3_GATE>;
				clock-names = "ipg", "ahb", "per";
				assigned-clocks = <&clk IMX91_CLK_USDHC3>;
				assigned-clock-parents = <&clk IMX91_CLK_SYS_PLL_PFD1>;
				assigned-clock-rates = <400000000>;
				bus-width = <4>;
				fsl,tuning-start-tap = <1>;
				fsl,tuning-step= <2>;
				status = "disabled";
			};

			isi: isi@4ae40000 {
				compatible = "fsl,imx91-isi";
				reg = <0x4ae40000 0x10000>;
				interrupts = <GIC_SPI 172 IRQ_TYPE_LEVEL_HIGH>;
				clocks = <&clk IMX91_CLK_ISI_GATE>,
					<&clk IMX91_CLK_MEDIA_AXI>;
				clock-names = "axi", "apb";
				assigned-clocks = <&clk IMX91_CLK_MEDIA_AXI>,
						<&clk IMX91_CLK_MEDIA_APB>;
				assigned-clock-parents = <&clk IMX91_CLK_SYS_PLL_PFD0>,
							<&clk IMX91_CLK_SYS_PLL_PFD0_DIV2>;
				assigned-clock-rates = <333333334>, <125000000>;
				power-domains = <&media_blk_ctrl IMX91_MEDIABLK_PD_ISI>;
				status = "disabled";
			};

			parallel_csi: pcsi@4ac10070 {
				compatible = "fsl,imx91-parallel-csi";
				reg = <0x4ac10070 0x10>;
				clocks = <&clk IMX91_CLK_MIPI_CSI_GATE>,
				<&clk IMX91_CLK_MEDIA_APB>;
				clock-names = "pixel", "ipg";
				assigned-clocks = <&clk IMX91_CLK_CAM_PIX>;
				assigned-clock-parents = <&clk IMX91_CLK_VIDEO_PLL>;
				assigned-clock-rates = <140000000>;
				power-domains = <&media_blk_ctrl IMX91_MEDIABLK_PD_MIPI_CSI>;
				status = "disabled";

				ports {
					#address-cells = <1>;
					#size-cells = <0>;

					port@0 {
						reg = <0>;
					};

					port@1 {
						reg = <1>;
					};
				};
			};
		};

		gpio2: gpio@43810080 {
			compatible = "fsl,imx93-gpio", "fsl,imx7ulp-gpio";
			reg = <0x43810080 0x1000>, <0x43810040 0x40>;
			gpio-controller;
			#gpio-cells = <2>;
			interrupts = <GIC_SPI 57 IRQ_TYPE_LEVEL_HIGH>;
			interrupt-controller;
			#interrupt-cells = <2>;
			clocks = <&clk IMX91_CLK_GPIO2_GATE>,
				 <&clk IMX91_CLK_GPIO2_GATE>;
			clock-names = "gpio", "port";
			gpio-ranges = <&iomuxc 0 4 30>;
		};

		gpio3: gpio@43820080 {
			compatible = "fsl,imx93-gpio", "fsl,imx7ulp-gpio";
			reg = <0x43820080 0x1000>, <0x43820040 0x40>;
			gpio-controller;
			#gpio-cells = <2>;
			interrupts = <GIC_SPI 59 IRQ_TYPE_LEVEL_HIGH>;
			interrupt-controller;
			#interrupt-cells = <2>;
			clocks = <&clk IMX91_CLK_GPIO3_GATE>,
				 <&clk IMX91_CLK_GPIO3_GATE>;
			clock-names = "gpio", "port";
			gpio-ranges = <&iomuxc 0 84 8>, <&iomuxc 8 66 18>,
				      <&iomuxc 26 34 2>, <&iomuxc 28 0 4>;
		};

		gpio4: gpio@43830080 {
			compatible = "fsl,imx93-gpio", "fsl,imx7ulp-gpio";
			reg = <0x43830080 0x1000>, <0x43830040 0x40>;
			gpio-controller;
			#gpio-cells = <2>;
			interrupts = <GIC_SPI 189 IRQ_TYPE_LEVEL_HIGH>;
			interrupt-controller;
			#interrupt-cells = <2>;
			clocks = <&clk IMX91_CLK_GPIO4_GATE>,
				 <&clk IMX91_CLK_GPIO4_GATE>;
			clock-names = "gpio", "port";
			gpio-ranges = <&iomuxc 0 38 28>, <&iomuxc 28 36 2>;
		};

		gpio1: gpio@47400080 {
			compatible = "fsl,imx93-gpio", "fsl,imx7ulp-gpio";
			reg = <0x47400080 0x1000>, <0x47400040 0x40>;
			gpio-controller;
			#gpio-cells = <2>;
			interrupts = <GIC_SPI 10 IRQ_TYPE_LEVEL_HIGH>;
			interrupt-controller;
			#interrupt-cells = <2>;
			clocks = <&clk IMX91_CLK_GPIO1_GATE>,
				 <&clk IMX91_CLK_GPIO1_GATE>;
			clock-names = "gpio", "port";
			gpio-ranges = <&iomuxc 0 92 16>;
		};

		ocotp: efuse@47510000 {
			compatible = "fsl,imx93-ocotp", "syscon", "simple-mfd";
			reg = <0x47510000 0x10000>;
			#address-cells = <1>;
			#size-cells = <1>;

			imx93_uid: soc-uid@c0 {
				reg = <0xc0 0x10>;
			};

			tmu_trim1: tmu-trim@a0 {
				reg = <0xa0 0x4>;
			};

			tmu_trim2: tmu-trim@a4 {
				reg = <0xa4 0x4>;
			};

			eth_mac1: mac-address@4ec {
				reg = <0x4ec 0x6>;
			};

			eth_mac2: mac-address@4f2 {
				reg = <0x4f2 0x6>;
			};

			imx93_soc: imx93-soc {
				compatible = "fsl,imx93-soc";
				nvmem-cells = <&imx93_uid>;
				nvmem-cell-names = "soc_unique_id";
			};
		};

		s4muap: mailbox@47520000 {
			compatible = "fsl,imx93-mu-s4";
			reg = <0x47520000 0x10000>;
			interrupts = <GIC_SPI 31 IRQ_TYPE_LEVEL_HIGH>,
				     <GIC_SPI 30 IRQ_TYPE_LEVEL_HIGH>;
			interrupt-names = "tx", "rx";
			#mbox-cells = <2>;
		};

		media_blk_ctrl: system-controller@4ac10000 {
			compatible = "fsl,imx93-media-blk-ctrl", "syscon", "simple-mfd";
			reg = <0x4ac10000 0x70>;
			power-domains = <&mediamix>;
			clocks = <&clk IMX91_CLK_MEDIA_APB>,
				 <&clk IMX91_CLK_MEDIA_AXI>,
				 <&clk IMX91_CLK_NIC_MEDIA_GATE>,
				 <&clk IMX91_CLK_MEDIA_DISP_PIX>,
				 <&clk IMX91_CLK_CAM_PIX>,
				 <&clk IMX91_CLK_PXP_GATE>,
				 <&clk IMX91_CLK_LCDIF_GATE>,
				 <&clk IMX91_CLK_ISI_GATE>,
				 <&clk IMX91_CLK_MIPI_CSI_GATE>,
				 <&clk IMX91_CLK_MIPI_DSI_GATE>;
			clock-names = "apb", "axi", "nic", "disp", "cam",
				      "pxp", "lcdif", "isi", "csi", "dsi";
			#power-domain-cells = <1>;

			parallel_disp_fmt: dpi {
				compatible = "fsl,imx93-parallel-display-format";
				power-domains = <&mediamix>;
				status = "disabled";

				ports {
					#address-cells = <1>;
					#size-cells = <0>;

					port@0 {
						reg = <0>;

						dpi_to_lcdif: endpoint {
							remote-endpoint = <&lcdif_to_dpi>;
						};
					};

					port@1 {
						reg = <1>;
						endpoint {
						};
					};
				};
			};
		};

		ddr: memory-controller@4e300000 {
			compatible = "nxp,imx9-memory-controller", "simple-mfd";
			reg = <0x4e300000 0x2000>;
			interrupts = <GIC_SPI 91 IRQ_TYPE_LEVEL_HIGH>;
			little-endian;
			#address-cells = <1>;
			#size-cells = <1>;
			ranges;

			ddr-pmu@4e300dc0 {
				compatible = "fsl,imx93-ddr-pmu";
				reg = <0x4e300dc0 0x200>;
				interrupts = <GIC_SPI 90 IRQ_TYPE_LEVEL_HIGH>;
			};
		};

		lcdif: lcd-controller@4ae30000 {
			compatible = "fsl,imx93-lcdif";
			reg = <0x4ae30000 0x10000>;
			interrupts = <GIC_SPI 176 IRQ_TYPE_LEVEL_HIGH>;
			fsl,gpr = <&media_blk_ctrl>;
			clocks = <&clk IMX91_CLK_MEDIA_DISP_PIX>,
				 <&clk IMX91_CLK_MEDIA_AXI>,
				 <&clk IMX91_CLK_LCDIF_GATE>;
			clock-names = "pix", "disp-axi", "disp-apb";
			assigned-clocks = <&clk IMX91_CLK_VIDEO_PLL>,
					  <&clk IMX91_CLK_MEDIA_DISP_PIX>,
					  <&clk IMX91_CLK_MEDIA_AXI>,
					  <&clk IMX91_CLK_MEDIA_APB>;
			assigned-clock-parents = <&clk IMX91_CLK_24M>,
						 <&clk IMX91_CLK_VIDEO_PLL>,
						 <&clk IMX91_CLK_SYS_PLL_PFD0>,
						 <&clk IMX91_CLK_SYS_PLL_PFD0_DIV2>;
			power-domains = <&media_blk_ctrl IMX91_MEDIABLK_PD_LCDIF>;
			status = "disabled";

			lcdif_disp: port {
				#address-cells = <1>;
				#size-cells = <0>;

				lcdif_to_dpi: endpoint@2 {
					reg = <2>;
					remote-endpoint = <&dpi_to_lcdif>;
				};
			};
		};

		usbotg1: usb@4c100000 {
			compatible = "fsl,imx8mm-usb", "fsl,imx7d-usb";
			reg = <0x4c100000 0x200>;
			interrupts = <GIC_SPI 187 IRQ_TYPE_LEVEL_HIGH>;
			clocks = <&clk IMX91_CLK_USB_CONTROLLER_GATE>,
				 <&clk IMX91_CLK_HSIO_32K_GATE>;
			clock-names = "usb_ctrl_root_clk", "usb_wakeup_clk";
			assigned-clocks = <&clk IMX91_CLK_HSIO>;
			assigned-clock-parents = <&clk IMX91_CLK_SYS_PLL_PFD1_DIV2>;
			assigned-clock-rates = <133000000>;
			fsl,usbphy = <&usbphynop1>;
			fsl,usbmisc = <&usbmisc1 0>;
			status = "disabled";
		};

		usbmisc1: usbmisc@4c100200 {
			compatible = "fsl,imx8mm-usbmisc", "fsl,imx7d-usbmisc";
			#index-cells = <1>;
			reg = <0x4c100200 0x200>;
		};

		usbotg2: usb@4c200000 {
			compatible = "fsl,imx8mm-usb", "fsl,imx7d-usb";
			reg = <0x4c200000 0x200>;
			interrupts = <GIC_SPI 188 IRQ_TYPE_LEVEL_HIGH>;
			clocks = <&clk IMX91_CLK_USB_CONTROLLER_GATE>,
				 <&clk IMX91_CLK_HSIO_32K_GATE>;
			clock-names = "usb_ctrl_root_clk", "usb_wakeup_clk";
			assigned-clocks = <&clk IMX91_CLK_HSIO>;
			assigned-clock-parents = <&clk IMX91_CLK_SYS_PLL_PFD1_DIV2>;
			assigned-clock-rates = <133000000>;
			fsl,usbphy = <&usbphynop2>;
			fsl,usbmisc = <&usbmisc2 0>;
			status = "disabled";
		};

		usbmisc2: usbmisc@4c200200 {
			compatible = "fsl,imx8mm-usbmisc", "fsl,imx7d-usbmisc";
			#index-cells = <1>;
			reg = <0x4c200200 0x200>;
		};

		ddrmix_blk_ctrl: blk-ctrl@4e010000 {
			compatible = "nxp,blk-ctrl-ddrmix", "syscon", "simple-mfd";
			reg = <0x4e010000 0x1000>;
		};
	};

	display-subsystem {
		compatible = "fsl,imx-display-subsystem";
		ports = <&lcdif_disp>;
	};

	lpm: imx93-lpm {
		compatible = "nxp,imx93-lpm";
		no-od-mode;
		regmap = <&ddrmix_blk_ctrl>;
		clocks = <&clk IMX91_CLK_M33>, <&clk IMX91_CLK_WAKEUP_AXI>,
			 <&clk IMX91_CLK_NIC_AXI>, <&clk IMX91_CLK_MEDIA_AXI>,
			 <&clk IMX91_CLK_MEDIA_APB>, <&clk IMX91_CLK_A55_PERIPH>,
			 <&clk IMX91_CLK_A55_CORE>, <&clk IMX91_CLK_DUMMY>,
			 <&clk IMX91_CLK_SYS_PLL_PFD0>, <&clk IMX91_CLK_SYS_PLL_PFD0_DIV2>,
			 <&clk IMX91_CLK_SYS_PLL_PFD1>, <&clk IMX91_CLK_SYS_PLL_PFD1_DIV2>,
			 <&clk IMX91_CLK_SYS_PLL_PFD2>, <&clk IMX91_CLK_SYS_PLL_PFD2_DIV2>;
		clock-names = "m33_root", "wakeup_axi", "nic_axi",
				  "media_axi", "media_apb", "a55_periph",
			      "a55_core", "ml_axi", "sys_pll_pfd0", "sys_pll_pfd0_div2",
			      "sys_pll_pfd1", "sys_pll_pfd1_div2", "sys_pll_pfd2",
			      "sys_pll_pfd2_div2";
		#cooling-cells = <2>;
		status = "disabled";
	};

	ele_fw2: secure-enclave {
		compatible = "fsl,imx93-se";
		mbox-names = "tx", "rx";
		mboxes = <&s4muap 0 0>,
			<&s4muap 1 0>;
	};
};
